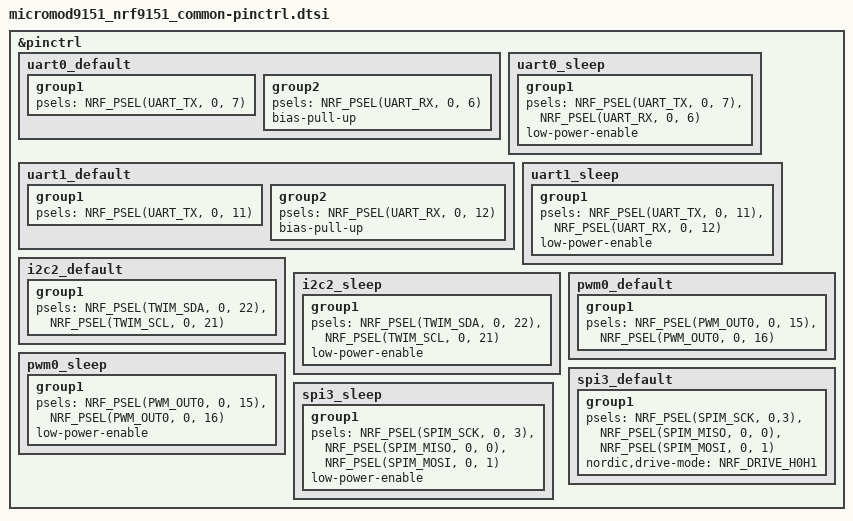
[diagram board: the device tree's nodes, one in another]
/*
 * Copyright (c) 2026 Christian Hirsch
 * SPDX-License-Identifier: Apache-2.0
 */

&pinctrl {
	uart0_default: uart0_default {
		group1 {
			psels = <NRF_PSEL(UART_TX, 0, 7)>;
		};
		group2 {
			psels = <NRF_PSEL(UART_RX, 0, 6)>;
			bias-pull-up;
		};
	};

	uart0_sleep: uart0_sleep {
		group1 {
			psels = <NRF_PSEL(UART_TX, 0, 7)>,
				<NRF_PSEL(UART_RX, 0, 6)>;
			low-power-enable;
		};
	};

	uart1_default: uart1_default {
		group1 {
			psels = <NRF_PSEL(UART_TX, 0, 11)>;
		};
		group2 {
			psels = <NRF_PSEL(UART_RX, 0, 12)>;
			bias-pull-up;
		};
	};

	uart1_sleep: uart1_sleep {
		group1 {
			psels = <NRF_PSEL(UART_TX, 0, 11)>,
				<NRF_PSEL(UART_RX, 0, 12)>;
			low-power-enable;
		};
	};

	i2c2_default: i2c2_default {
		group1 {
			psels = <NRF_PSEL(TWIM_SDA, 0, 22)>,
				<NRF_PSEL(TWIM_SCL, 0, 21)>;
		};
	};

	i2c2_sleep: i2c2_sleep {
		group1 {
			psels = <NRF_PSEL(TWIM_SDA, 0, 22)>,
				<NRF_PSEL(TWIM_SCL, 0, 21)>;
			low-power-enable;
		};
	};

	pwm0_default: pwm0_default {
		group1 {
			psels = <NRF_PSEL(PWM_OUT0, 0, 15)>,
				<NRF_PSEL(PWM_OUT0, 0, 16)>;
		};
	};

	pwm0_sleep: pwm0_sleep {
		group1 {
			psels = <NRF_PSEL(PWM_OUT0, 0, 15)>,
				<NRF_PSEL(PWM_OUT0, 0, 16)>;
			low-power-enable;
		};
	};

	spi3_default: spi3_default {
		group1 {
			psels = <NRF_PSEL(SPIM_SCK, 0,3)>,
				<NRF_PSEL(SPIM_MISO, 0, 0)>,
				<NRF_PSEL(SPIM_MOSI, 0, 1)>;
			nordic,drive-mode = <NRF_DRIVE_H0H1>;
		};
	};

	spi3_sleep: spi3_sleep {
		group1 {
			psels = <NRF_PSEL(SPIM_SCK, 0, 3)>,
				<NRF_PSEL(SPIM_MISO, 0, 0)>,
				<NRF_PSEL(SPIM_MOSI, 0, 1)>;
			low-power-enable;
		};
	};
};
